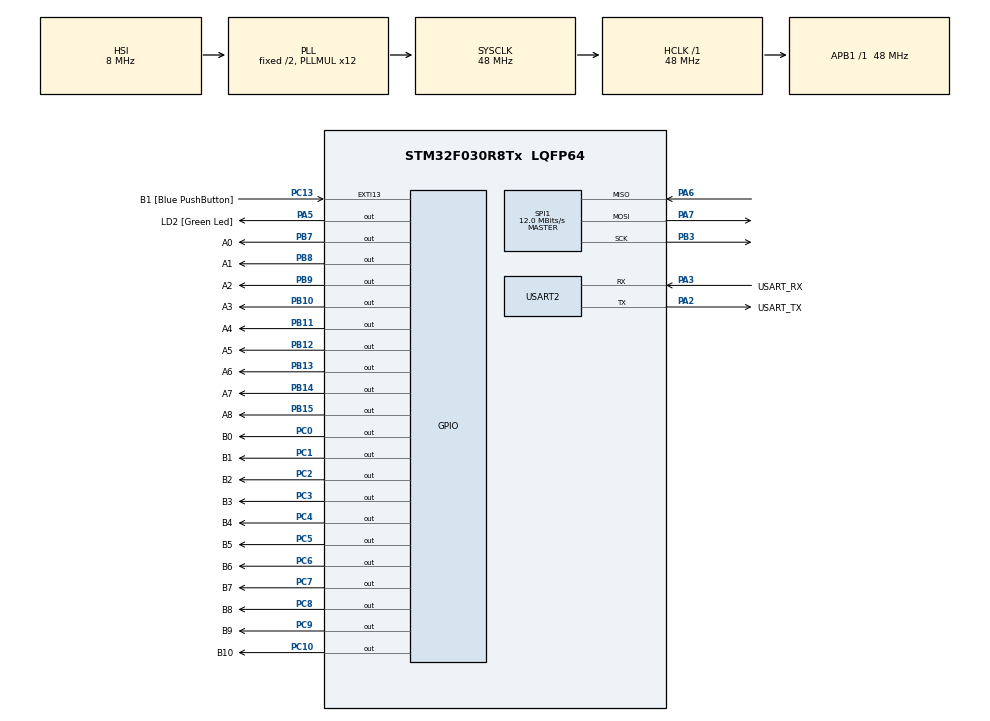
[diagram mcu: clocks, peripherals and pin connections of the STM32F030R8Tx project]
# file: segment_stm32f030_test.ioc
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FREERTOS.Tasks01=defaultTask,24,128,StartDefaultTask,As weak,NULL,Dynamic,NULL,NULL;subTask,24,128,StartSubTask,As weak,NULL,Dynamic,NULL,NULL
Mcu.Family=STM32F0
Mcu.Name=STM32F030R8Tx
Mcu.Package=LQFP64
NVIC.EXTI4_15_IRQn=true\:3\:0\:false\:false\:true\:true\:true\:true\:true
PA13.GPIO_Label=TMS
PA13.Mode=Serial_Wire
PA13.Signal=SYS_SWDIO
PA14.GPIO_Label=TCK
PA14.Mode=Serial_Wire
PA14.Signal=SYS_SWCLK
PA2.GPIO_Label=USART_TX
PA2.GPIO_Mode=GPIO_MODE_AF_PP
PA2.GPIO_PuPd=GPIO_NOPULL
PA2.GPIO_Speed=GPIO_SPEED_FREQ_LOW
PA2.Mode=Asynchronous
PA2.Signal=USART2_TX
PA3.GPIO_Label=USART_RX
PA3.GPIO_Mode=GPIO_MODE_AF_PP
PA3.GPIO_PuPd=GPIO_NOPULL
PA3.GPIO_Speed=GPIO_SPEED_FREQ_LOW
PA3.Mode=Asynchronous
PA3.Signal=USART2_RX
PA5.GPIO_Label=LD2 [Green Led]
PA5.GPIO_Mode=GPIO_MODE_OUTPUT_PP
PA5.GPIO_PuPd=GPIO_NOPULL
PA5.GPIO_Speed=GPIO_SPEED_FREQ_LOW
PA5.Signal=GPIO_Output
PA6.Mode=Full_Duplex_Master
PA6.Signal=SPI1_MISO
PA7.Mode=Full_Duplex_Master
PA7.Signal=SPI1_MOSI
PB10.GPIO_Label=A3
PB10.GPIO_Speed=GPIO_SPEED_FREQ_HIGH
PB10.Signal=GPIO_Output
PB11.GPIO_Label=A4
PB11.GPIO_Speed=GPIO_SPEED_FREQ_HIGH
PB11.Signal=GPIO_Output
PB12.GPIO_Label=A5
PB12.GPIO_Speed=GPIO_SPEED_FREQ_HIGH
PB12.Signal=GPIO_Output
PB13.GPIO_Label=A6
PB13.GPIO_Speed=GPIO_SPEED_FREQ_HIGH
PB13.Signal=GPIO_Output
PB14.GPIO_Label=A7
PB14.GPIO_Speed=GPIO_SPEED_FREQ_HIGH
PB14.Signal=GPIO_Output
PB15.GPIO_Label=A8
PB15.GPIO_Speed=GPIO_SPEED_FREQ_HIGH
PB15.Signal=GPIO_Output
PB3.Mode=Full_Duplex_Master
PB3.Signal=SPI1_SCK
PB7.GPIO_FM7=SYSCFG_CFGR1_I2C_FMP_PB7
PB7.GPIO_Label=A0
PB7.GPIO_Speed=GPIO_SPEED_FREQ_HIGH
PB7.Signal=GPIO_Output
PB8.GPIO_FM8=SYSCFG_CFGR1_I2C_FMP_PB8
PB8.GPIO_Label=A1
PB8.GPIO_Speed=GPIO_SPEED_FREQ_HIGH
PB8.Signal=GPIO_Output
PB9.GPIO_FM9=SYSCFG_CFGR1_I2C_FMP_PB9
PB9.GPIO_Label=A2
PB9.GPIO_Speed=GPIO_SPEED_FREQ_HIGH
PB9.Signal=GPIO_Output
PC0.GPIO_Label=B0
PC0.GPIO_Speed=GPIO_SPEED_FREQ_HIGH
PC0.Signal=GPIO_Output
PC1.GPIO_Label=B1
PC1.GPIO_Speed=GPIO_SPEED_FREQ_HIGH
PC1.Signal=GPIO_Output
PC10.GPIO_Label=B10
PC10.GPIO_Speed=GPIO_SPEED_FREQ_HIGH
PC10.Signal=GPIO_Output
PC13.GPIO_Label=B1 [Blue PushButton]
PC13.GPIO_ModeDefaultEXTI=GPIO_MODE_IT_FALLING
PC13.Signal=GPXTI13
PC14-OSC32_IN.Mode=LSE-External-Oscillator
PC14-OSC32_IN.Signal=RCC_OSC32_IN
PC15-OSC32_OUT.Mode=LSE-External-Oscillator
PC15-OSC32_OUT.Signal=RCC_OSC32_OUT
PC2.GPIO_Label=B2
PC2.GPIO_Speed=GPIO_SPEED_FREQ_HIGH
PC2.Signal=GPIO_Output
PC3.GPIO_Label=B3
PC3.GPIO_Speed=GPIO_SPEED_FREQ_HIGH
PC3.Signal=GPIO_Output
PC4.GPIO_Label=B4
PC4.GPIO_Speed=GPIO_SPEED_FREQ_HIGH
PC4.Signal=GPIO_Output
PC5.GPIO_Label=B5
PC5.GPIO_Speed=GPIO_SPEED_FREQ_HIGH
PC5.Signal=GPIO_Output
PC6.GPIO_Label=B6
PC6.GPIO_Speed=GPIO_SPEED_FREQ_HIGH
PC6.Signal=GPIO_Output
PC7.GPIO_Label=B7
PC7.GPIO_Speed=GPIO_SPEED_FREQ_HIGH
PC7.Signal=GPIO_Output
PC8.GPIO_Label=B8
PC8.GPIO_Speed=GPIO_SPEED_FREQ_HIGH
PC8.Signal=GPIO_Output
PC9.GPIO_Label=B9
PC9.GPIO_Speed=GPIO_SPEED_FREQ_HIGH
PC9.Signal=GPIO_Output
PF0-OSC_IN.Mode=HSE-External-Clock-Source
PF0-OSC_IN.Signal=RCC_OSC_IN
PF1-OSC_OUT.Signal=RCC_OSC_OUT
ProjectManager.HeapSize=0x200
ProjectManager.StackSize=0x400
ProjectManager.TargetToolchain=EWARM V8.32
RCC.AHBFreq_Value=48000000
RCC.APB1Freq_Value=48000000
RCC.APB1TimFreq_Value=48000000
RCC.HCLKFreq_Value=48000000
RCC.PLLMUL=RCC_PLL_MUL12
RCC.SYSCLKFreq_VALUE=48000000
RCC.SYSCLKSource=RCC_SYSCLKSOURCE_PLLCLK
SPI1.BaudRatePrescaler=SPI_BAUDRATEPRESCALER_4
SPI1.CalculateBaudRate=12.0 MBits/s
SPI1.Direction=SPI_DIRECTION_2LINES
SPI1.Mode=SPI_MODE_MASTER
SPI1.VirtualType=VM_MASTER
USART2.VirtualMode-Asynchronous=VM_ASYNC
VP_FREERTOS_VS_CMSIS_V2.Mode=CMSIS_V2
board=NUCLEO-F030R8

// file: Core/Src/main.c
/* USER CODE BEGIN Header */
/**
  ******************************************************************************
  * @file           : main.c
  * @brief          : Main program body
  ******************************************************************************
  * @attention
  *
  * Copyright (c) 2023 STMicroelectronics.
  * All rights reserved.
  *
  * This software is licensed under terms that can be found in the LICENSE file
  * in the root directory of this software component.
  * If no LICENSE file comes with this software, it is provided AS-IS.
  *
  ******************************************************************************
  */
/* USER CODE END Header */
#include "main.h"
#include "cmsis_os.h"

/* USER CODE BEGIN Includes */
#include "../../Main/Inc/user_main.h"
/* USER CODE END Includes */

SPI_HandleTypeDef hspi1;

UART_HandleTypeDef huart2;

/* Definitions for defaultTask */
osThreadId_t defaultTaskHandle;
const osThreadAttr_t defaultTask_attributes = {
  .name = "defaultTask",
  .stack_size = 128 * 4,
  .priority = (osPriority_t) osPriorityNormal,
};
/* Definitions for subTask */
osThreadId_t subTaskHandle;
const osThreadAttr_t subTask_attributes = {
  .name = "subTask",
  .stack_size = 128 * 4,
  .priority = (osPriority_t) osPriorityNormal,
};

void SystemClock_Config(void);
static void MX_GPIO_Init(void);
static void MX_USART2_UART_Init(void);
static void MX_SPI1_Init(void);
void StartDefaultTask(void *argument);
void StartSubTask(void *argument);

int main(void)
{

  /* MCU Configuration--------------------------------------------------------*/

  /* Reset of all peripherals, Initializes the Flash interface and the Systick. */
  HAL_Init();

  /* Configure the system clock */
  SystemClock_Config();

  /* Initialize all configured peripherals */
  MX_GPIO_Init();
  MX_USART2_UART_Init();
  MX_SPI1_Init();

  /* Init scheduler */
  osKernelInitialize();

  /* Create the thread(s) */
  /* creation of defaultTask */
  defaultTaskHandle = osThreadNew(StartDefaultTask, NULL, &defaultTask_attributes);

  /* creation of subTask */
  subTaskHandle = osThreadNew(StartSubTask, NULL, &subTask_attributes);

  /* Start scheduler */
  osKernelStart();

  /* We should never get here as control is now taken by the scheduler */
  /* Infinite loop */
  while (1)
  {

  }
}

void SystemClock_Config(void)
{
  RCC_OscInitTypeDef RCC_OscInitStruct = {0};
  RCC_ClkInitTypeDef RCC_ClkInitStruct = {0};

  /** Initializes the RCC Oscillators according to the specified parameters
  * in the RCC_OscInitTypeDef structure.
  */
  RCC_OscInitStruct.OscillatorType = RCC_OSCILLATORTYPE_HSI;
  RCC_OscInitStruct.HSIState = RCC_HSI_ON;
  RCC_OscInitStruct.HSICalibrationValue = RCC_HSICALIBRATION_DEFAULT;
  RCC_OscInitStruct.PLL.PLLState = RCC_PLL_ON;
  RCC_OscInitStruct.PLL.PLLSource = RCC_PLLSOURCE_HSI;
  RCC_OscInitStruct.PLL.PLLMUL = RCC_PLL_MUL12;
  RCC_OscInitStruct.PLL.PREDIV = RCC_PREDIV_DIV1;
  if (HAL_RCC_OscConfig(&RCC_OscInitStruct) != HAL_OK)
  {
    Error_Handler();
  }

  /** Initializes the CPU, AHB and APB buses clocks
  */
  RCC_ClkInitStruct.ClockType = RCC_CLOCKTYPE_HCLK|RCC_CLOCKTYPE_SYSCLK
                              |RCC_CLOCKTYPE_PCLK1;
  RCC_ClkInitStruct.SYSCLKSource = RCC_SYSCLKSOURCE_PLLCLK;
  RCC_ClkInitStruct.AHBCLKDivider = RCC_SYSCLK_DIV1;
  RCC_ClkInitStruct.APB1CLKDivider = RCC_HCLK_DIV1;

  if (HAL_RCC_ClockConfig(&RCC_ClkInitStruct, FLASH_LATENCY_1) != HAL_OK)
  {
    Error_Handler();
  }
}

static void MX_SPI1_Init(void)
{

  /* SPI1 parameter configuration*/
  hspi1.Instance = SPI1;
  hspi1.Init.Mode = SPI_MODE_MASTER;
  hspi1.Init.Direction = SPI_DIRECTION_2LINES;
  hspi1.Init.DataSize = SPI_DATASIZE_4BIT;
  hspi1.Init.CLKPolarity = SPI_POLARITY_LOW;
  hspi1.Init.CLKPhase = SPI_PHASE_1EDGE;
  hspi1.Init.NSS = SPI_NSS_SOFT;
  hspi1.Init.BaudRatePrescaler = SPI_BAUDRATEPRESCALER_4;
  hspi1.Init.FirstBit = SPI_FIRSTBIT_MSB;
  hspi1.Init.TIMode = SPI_TIMODE_DISABLE;
  hspi1.Init.CRCCalculation = SPI_CRCCALCULATION_DISABLE;
  hspi1.Init.CRCPolynomial = 7;
  hspi1.Init.CRCLength = SPI_CRC_LENGTH_DATASIZE;
  hspi1.Init.NSSPMode = SPI_NSS_PULSE_ENABLE;
  if (HAL_SPI_Init(&hspi1) != HAL_OK)
  {
    Error_Handler();
  }

}

static void MX_USART2_UART_Init(void)
{

  huart2.Instance = USART2;
  huart2.Init.BaudRate = 38400;
  huart2.Init.WordLength = UART_WORDLENGTH_8B;
  huart2.Init.StopBits = UART_STOPBITS_1;
  huart2.Init.Parity = UART_PARITY_NONE;
  huart2.Init.Mode = UART_MODE_TX_RX;
  huart2.Init.HwFlowCtl = UART_HWCONTROL_NONE;
  huart2.Init.OverSampling = UART_OVERSAMPLING_16;
  huart2.Init.OneBitSampling = UART_ONE_BIT_SAMPLE_DISABLE;
  huart2.AdvancedInit.AdvFeatureInit = UART_ADVFEATURE_NO_INIT;
  if (HAL_UART_Init(&huart2) != HAL_OK)
  {
    Error_Handler();
  }

}

static void MX_GPIO_Init(void)
{
  GPIO_InitTypeDef GPIO_InitStruct = {0};

  /* GPIO Ports Clock Enable */
  __HAL_RCC_GPIOC_CLK_ENABLE();
  __HAL_RCC_GPIOF_CLK_ENABLE();
  __HAL_RCC_GPIOA_CLK_ENABLE();
  __HAL_RCC_GPIOB_CLK_ENABLE();

  /*Configure GPIO pin Output Level */
  HAL_GPIO_WritePin(GPIOC, B0_Pin|B1C1_Pin|B2_Pin|B3_Pin
                          |B4_Pin|B5_Pin|B6_Pin|B7_Pin
                          |B8_Pin|B9_Pin|B10_Pin, GPIO_PIN_RESET);

  /*Configure GPIO pin Output Level */
  HAL_GPIO_WritePin(LD2_GPIO_Port, LD2_Pin, GPIO_PIN_RESET);

  /*Configure GPIO pin Output Level */
  HAL_GPIO_WritePin(GPIOB, A3_Pin|A4_Pin|A5_Pin|A6_Pin
                          |A7_Pin|A8_Pin|A0_Pin|A1_Pin
                          |A2_Pin, GPIO_PIN_RESET);

  /*Configure GPIO pin : B1_Pin */
  GPIO_InitStruct.Pin = B1_Pin;
  GPIO_InitStruct.Mode = GPIO_MODE_IT_FALLING;
  GPIO_InitStruct.Pull = GPIO_NOPULL;
  HAL_GPIO_Init(B1_GPIO_Port, &GPIO_InitStruct);

  /*Configure GPIO pins : B0_Pin B1C1_Pin B2_Pin B3_Pin
                           B4_Pin B5_Pin B6_Pin B7_Pin
                           B8_Pin B9_Pin B10_Pin */
  GPIO_InitStruct.Pin = B0_Pin|B1C1_Pin|B2_Pin|B3_Pin
                          |B4_Pin|B5_Pin|B6_Pin|B7_Pin
                          |B8_Pin|B9_Pin|B10_Pin;
  GPIO_InitStruct.Mode = GPIO_MODE_OUTPUT_PP;
  GPIO_InitStruct.Pull = GPIO_NOPULL;
  GPIO_InitStruct.Speed = GPIO_SPEED_FREQ_HIGH;
  HAL_GPIO_Init(GPIOC, &GPIO_InitStruct);

  /*Configure GPIO pin : LD2_Pin */
  GPIO_InitStruct.Pin = LD2_Pin;
  GPIO_InitStruct.Mode = GPIO_MODE_OUTPUT_PP;
  GPIO_InitStruct.Pull = GPIO_NOPULL;
  GPIO_InitStruct.Speed = GPIO_SPEED_FREQ_LOW;
  HAL_GPIO_Init(LD2_GPIO_Port, &GPIO_InitStruct);

  /*Configure GPIO pins : A3_Pin A4_Pin A5_Pin A6_Pin
                           A7_Pin A8_Pin A0_Pin A1_Pin
                           A2_Pin */
  GPIO_InitStruct.Pin = A3_Pin|A4_Pin|A5_Pin|A6_Pin
                          |A7_Pin|A8_Pin|A0_Pin|A1_Pin
                          |A2_Pin;
  GPIO_InitStruct.Mode = GPIO_MODE_OUTPUT_PP;
  GPIO_InitStruct.Pull = GPIO_NOPULL;
  GPIO_InitStruct.Speed = GPIO_SPEED_FREQ_HIGH;
  HAL_GPIO_Init(GPIOB, &GPIO_InitStruct);

  /**/
  HAL_I2CEx_EnableFastModePlus(SYSCFG_CFGR1_I2C_FMP_PB7);

  /**/
  HAL_I2CEx_EnableFastModePlus(SYSCFG_CFGR1_I2C_FMP_PB8);

  /**/
  HAL_I2CEx_EnableFastModePlus(SYSCFG_CFGR1_I2C_FMP_PB9);

  /* EXTI interrupt init*/
  HAL_NVIC_SetPriority(EXTI4_15_IRQn, 3, 0);
  HAL_NVIC_EnableIRQ(EXTI4_15_IRQn);

}

__weak void StartDefaultTask(void *argument)
{
  for(;;)
  {
    osDelay(1);
  }
}

__weak void StartSubTask(void *argument)
{
  for(;;)
  {
    osDelay(1);
  }
}

void Error_Handler(void)
{
  __disable_irq();
  while (1)
  {
  }
}
